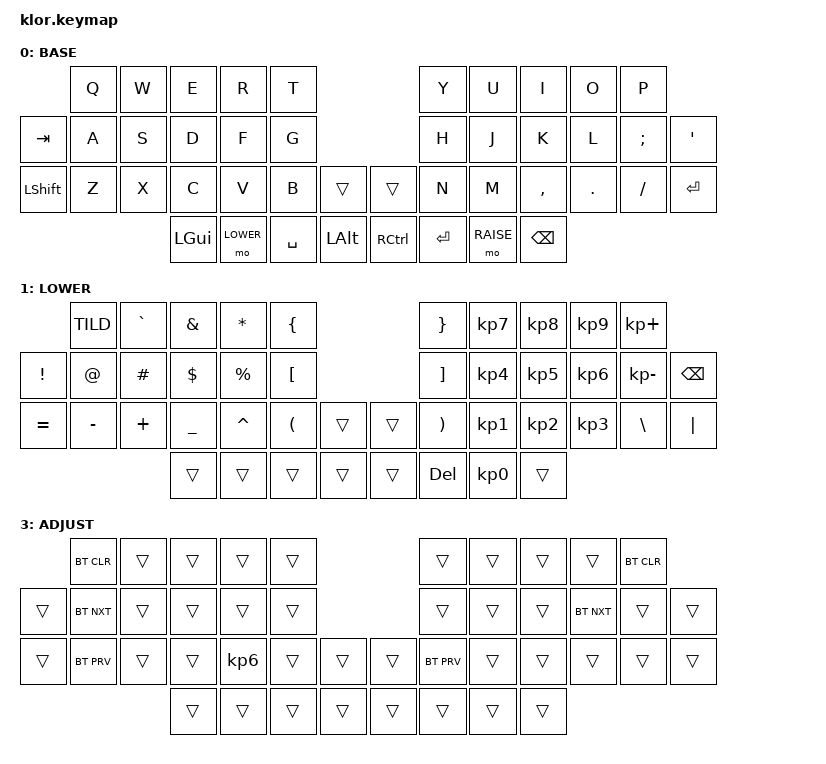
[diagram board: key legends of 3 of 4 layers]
//                               █         █    █            ▄▄▄▀▀▀▀▀▀▄▄▄        █▀▀▀▀▀▀▀▀▀▀█
//                               █        █     █          ▄▀            ▀▄      █          █
//                               █       █      █        ▄▀                ▀▄    █          █
//                               █      █       █        █                  █    █          █
//                               █     █        █       █                    █   █          █
//                               █    █         █       █                    █   █▄▄▄▄▄▄▄▄▄▄█
//                               █   █ █        █       █                    █   █      █
//                               █  █   █       █        █                  █    █       █
//                               █ █     █      █        ▀▄                ▄▀    █        █
//                               ██       █     █          ▀▄            ▄▀      █         █
//                               █         █    █▄▄▄▄▄▄▄▄    ▀▀▀▄▄▄▄▄▄▀▀▀        █          █
//
// ▄▄▄▄▄▄▄▄▄▄▄▄▄▄▄▄▄▄▄▄▄▄▄▄▄▄▄▄▄▄▄▄▄▄▄▄▄▄▄▄▄▄▄▄▄▄▄▄▄▄▄▄▄▄▄▄▄▄▄▄▄▄▄▄▄▄▄▄▄▄▄▄▄▄▄▄▄▄▄▄▄▄▄▄▄▄▄▄▄▄▄▄▄▄▄▄▄▄▄▄▄▄▄▄▄▄▄▄▄▄▄▄▄▄▄▄▄▄▄▄▄▄▄▄▄

#include <behaviors.dtsi>
#include <dt-bindings/zmk/keys.h>
#include <dt-bindings/zmk/bt.h>
#include <dt-bindings/zmk/outputs.h>
#include <dt-bindings/zmk/ext_power.h>
#include <dt-bindings/zmk/rgb.h>

#define BASE   0
#define LOWER  1
#define RAISE  2
#define ADJUST 3

/ {
    behaviors {
        hm: homerow_mods {
            compatible = "zmk,behavior-hold-tap";
            label = "HOMEROW_MODS";
            #binding-cells = <2>;
            tapping-term-ms = <150>;
            quick_tap_ms = <0>;
            flavor = "tap-preferred";
            bindings = <&kp>, <&kp>;
        };

    };

     combos {
            compatible = "zmk,combos";
            combo_esc {
                timeout-ms = <50>;
                key-positions = <0 1>;
                bindings = <&kp ESC>;
            };
    };


        keymap {
                compatible = "zmk,keymap";
// ▄▄▄▄▄▄▄▄▄▄▄▄▄▄▄▄▄▄▄▄▄▄▄▄▄▄▄▄▄▄▄▄▄▄▄▄▄▄▄▄▄▄▄▄▄▄▄▄▄▄▄▄▄▄▄▄▄▄▄▄▄▄▄▄▄▄▄▄▄▄▄▄▄▄▄▄▄▄▄▄▄▄▄▄▄▄▄▄▄▄▄▄▄▄▄▄▄▄▄▄▄▄▄▄▄▄▄▄▄▄▄▄▄▄▄▄▄▄▄▄▄▄▄▄▄▄▄▄▄▄▄▄▄▄▄▄▄▄▄▄▄▄


                base_layer {
// ┌───────────────────────────────────────────────────────────┐
label= "BASE"                                                  ;
// └───────────────────────────────────────────────────────────┘
/*           ┌─────────┬─────────┬─────────┬─────────┬─────────┐                    ┌─────────┬─────────┬─────────┬─────────┬─────────┐
             │    Q    │    W    │    E    │    R    │    T    │                    │    Y    │    U    │    I    │    O    │    P    │
   ┌─────────┼─────────┼─────────┼─────────┼─────────┼─────────┤                    ├─────────┼─────────┼─────────┼─────────┼─────────┼─────────┐
   │   TAB   │    A    │    S    │    D    │    F    │    G    │                    │    H    │    J    │    K    │    L    │    ;    │    '    │
   ├─────────┼─────────┼─────────┼─────────┼─────────┼─────────┤╭────────╮╭────────╮├─────────┼─────────┼─────────┼─────────┼─────────┼─────────┤
   │ LSHIFT  │    Z    │    X    │    C    │    V    │    B    ││  MUTE  ││PLY/PSE ││    N    │    M    │    ,    │    .    │    /    │  ENTER  │
   └─────────┴─────────┴─────────┼─────────┼─────────┼─────────┼╰────────╯╰────────╯┼─────────┼─────────┼─────────┼─────────┴─────────┴─────────┘
                                 │ CMD/WIN │  LOWER  │   ALT   │  SPACE  ││   CTRL  │  ENTER  │  RAISE  │  BSPCE  │
                                 └─────────┴─────────┴─────────┴─────────┘└─────────┴─────────┴─────────┴─────────┘ */
 bindings = <
 //╷         ╷         ╷         ╷         ╷         ╷         ╷         ╷╷         ╷         ╷         ╷         ╷         ╷         ╷         ╷
              &kp Q     &kp W     &kp E     &kp R     &kp T                          &kp Y     &kp U     &kp I     &kp O     &kp P
    &kp TAB   &kp A     &kp S     &kp D   &kp F &kp G                          &kp H   &kp J &kp K     &kp L     &kp SEMI  &kp SQT
    &kp LSHIFT   &kp Z     &kp X     &kp C     &kp V     &kp B     &trans     &trans    &kp N     &kp M     &kp COMMA &kp DOT   &kp FSLH  &kp RET
                                  &kp LGUI &mo LOWER &kp SPACE  &kp LALT  &kp RCTRL  &kp RET   &mo RAISE &kp BSPC
                        >;
            sensor-bindings = <&inc_dec_kp C_VOL_UP C_VOL_DN>;
                };

// ▄▄▄▄▄▄▄▄▄▄▄▄▄▄▄▄▄▄▄▄▄▄▄▄▄▄▄▄▄▄▄▄▄▄▄▄▄▄▄▄▄▄▄▄▄▄▄▄▄▄▄▄▄▄▄▄▄▄▄▄▄▄▄▄▄▄▄▄▄▄▄▄▄▄▄▄▄▄▄▄▄▄▄▄▄▄▄▄▄▄▄▄▄▄▄▄▄▄▄▄▄▄▄▄▄▄▄▄▄▄▄▄▄▄▄▄▄▄▄▄▄▄▄▄▄▄▄▄▄▄▄▄▄▄▄▄▄▄▄▄▄▄



                lower_layer {
// ┌───────────────────────────────────────────────────────────┐
label= "LOWER"                                                 ;
// └───────────────────────────────────────────────────────────┘
/*           ┌─────────┬─────────┬─────────┬─────────┬─────────┐                    ┌─────────┬─────────┬─────────┬─────────┬─────────┐
             │     ~   │     `   │     &   │    *    │    {    │                    │    }    │    7    │    8    │    9    │    +    │
   ┌─────────┼─────────┼─────────┼─────────┼─────────┼─────────┤                    ├─────────┼─────────┼─────────┼─────────┼─────────┼─────────┐
   │    !    │    @    │    #    │    $    │    %    │    [    │                    │    ]    │    4    │    5    │    6    │    -    │  BSPCE  │
   ├─────────┼─────────┼─────────┼─────────┼─────────┼─────────┤╭────────╮╭────────╮├─────────┼─────────┼─────────┼─────────┼─────────┼─────────┤
   │    =    │    -    │    +    │   _     │  ^      │    (    ││        ││        ││    )    │    1    │    2    │    3    │    \    │    |    │
   └─────────┴─────────┴─────────┼─────────┼─────────┼─────────┼╰────────╯╰────────╯┼─────────┼─────────┼─────────┼─────────┴─────────┴─────────┘
                                 │         │         │         │         ││         │         │    0    │         │
                                 └─────────┴─────────┴─────────┴─────────┘└─────────┴─────────┴─────────┴─────────┘ */ 
 bindings = <
 //╷         ╷         ╷         ╷         ╷         ╷         ╷         ╷╷         ╷         ╷         ╷         ╷         ╷         ╷         ╷
    &kp TILD   &kp GRAVE    &kp AMPS    &kp ASTRK    &kp LBRC                       &kp RBRC  &kp KP_N7 &kp KP_N8 &kp KP_N9 &kp KP_PLUS
    &kp EXCL  &kp AT    &kp HASH  &kp DLLR  &kp PERCENT &kp LBKT                       &kp RBKT  &kp KP_N4 &kp KP_N5 &kp KP_N6 &kp KP_MINUS &kp BSPC
    &kp EQUAL &kp MINUS   &kp PLUS &kp UNDER  &kp CARET &kp LPAR  &trans     &trans    &kp RPAR  &kp KP_N1 &kp KP_N2 &kp KP_N3 &kp BSLH &kp PIPE
                                  &trans    &trans    &trans    &trans     &trans    &kp DELETE &kp KP_N0 &trans
                        >;
            sensor-bindings = <&inc_dec_kp C_VOL_UP C_VOL_DN>;
                };

// ▄▄▄▄▄▄▄▄▄▄▄▄▄▄▄▄▄▄▄▄▄▄▄▄▄▄▄▄▄▄▄▄▄▄▄▄▄▄▄▄▄▄▄▄▄▄▄▄▄▄▄▄▄▄▄▄▄▄▄▄▄▄▄▄▄▄▄▄▄▄▄▄▄▄▄▄▄▄▄▄▄▄▄▄▄▄▄▄▄▄▄▄▄▄▄▄▄▄▄▄▄▄▄▄▄▄▄▄▄▄▄▄▄▄▄▄▄▄▄▄▄▄▄▄▄


                raise_layer {
// ┌───────────────────────────────────────────────────────────┐
label= "RAISE"                                                 ;
// └───────────────────────────────────────────────────────────┘
/*           ┌─────────┬─────────┬─────────┬─────────┬─────────┐                    ┌─────────┬─────────┬─────────┬─────────┬─────────┐
             │         │    F1   │    F2   │    F3   │    F4   │                    │         │         │   UP    │         │         │
   ┌─────────┼─────────┼─────────┼─────────┼─────────┼─────────┤                    ├─────────┼─────────┼─────────┼─────────┼─────────┼─────────┐
   │    Ä    │         │    F5   │    F6   │    F7   │    F8   │                    │         │   LEFT  │  DOWN   │  RIGHT  │    Ö    │         │
   ├─────────┼─────────┼─────────┼─────────┼─────────┼─────────┤╭────────╮╭────────╮├─────────┼─────────┼─────────┼─────────┼─────────┼─────────┤
   │         │         │    F9   │   F10   │   F11   │   F12   ││        ││        ││         │   P UP  │         │ P DOWN  │         │         │
   └─────────┴─────────┴─────────┼─────────┼─────────┼─────────┼╰────────╯╰────────╯┼─────────┼─────────┼─────────┼─────────┴─────────┴─────────┘
                                 │ ADJUST  │         │         │         ││  C LOCK │         │         │         │
                                 └─────────┴─────────┴─────────┴─────────┘└─────────┴─────────┴─────────┴─────────┘ */
 bindings = <
 //╷         ╷         ╷         ╷         ╷         ╷         ╷         ╷╷         ╷         ╷         ╷         ╷         ╷         ╷         ╷
              &trans    &trans    &trans    &trans    &trans                         &trans    &trans    &kp UP &trans    &trans
    &kp RA(A) &trans    &kp RA(S) &trans    &trans    &trans                         &trans    &kp LEFT  &kp DOWN  &kp RIGHT    &kp RA(O) &trans
    &trans    &trans    &trans    &trans    &trans    &trans    &trans     &trans    &trans    &kp PG_UP   &kp &trans   &kp PG_DN    &trans    &trans
                                  &mo ADJUST &trans   &trans    &trans     &kp &trans    &trans    &trans    &trans
                        >;
                sensor-bindings = <&inc_dec_kp C_VOL_UP C_VOL_DN>;
                };

// ▄▄▄▄▄▄▄▄▄▄▄▄▄▄▄▄▄▄▄▄▄▄▄▄▄▄▄▄▄▄▄▄▄▄▄▄▄▄▄▄▄▄▄▄▄▄▄▄▄▄▄▄▄▄▄▄▄▄▄▄▄▄▄▄▄▄▄▄▄▄▄▄▄▄▄▄▄▄▄▄▄▄▄▄▄▄▄▄▄▄▄▄▄▄▄▄▄▄▄▄▄▄▄▄▄▄▄▄▄▄▄▄▄▄▄▄▄▄▄▄▄▄▄▄▄


                adjust_layer {
// ┌───────────────────────────────────────────────────────────┐
label= "ADJUST"                                                ;
// └───────────────────────────────────────────────────────────┘
/*           ┌─────────┬─────────┬─────────┬─────────┬─────────┐                    ┌─────────┬─────────┬─────────┬─────────┬─────────┐
             │         │         │         │         │         │                    │         │         │         │         │         │
   ┌─────────┼─────────┼─────────┼─────────┼─────────┼─────────┤                    ├─────────┼─────────┼─────────┼─────────┼─────────┼─────────┐
   │         │         │         │         │         │         │                    │         │         │         │         │         │         │
   ├─────────┼─────────┼─────────┼─────────┼─────────┼─────────┤╭────────╮╭────────╮├─────────┼─────────┼─────────┼─────────┼─────────┼─────────┤
   │         │         │         │         │         │         ││        ││        ││         │         │         │         │         │         │
   └─────────┴─────────┴─────────┼─────────┼─────────┼─────────┼╰────────╯╰────────╯┼─────────┼─────────┼─────────┼─────────┴─────────┴─────────┘
                                 │         │         │         │         ││         │         │         │         │
                                 └─────────┴─────────┴─────────┴─────────┘└─────────┴─────────┴─────────┴─────────┘ */
 bindings = <
 //╷         ╷         ╷         ╷         ╷         ╷         ╷         ╷╷         ╷         ╷         ╷         ╷         ╷         ╷         ╷
             &bt BT_CLR &trans    &trans    &trans    &trans                         &trans    &trans    &trans    &trans    &bt BT_CLR
    &trans   &bt BT_NXT &trans    &trans    &trans    &trans                         &trans    &trans    &trans    &bt BT_NXT &trans   &trans
    &trans   &bt BT_PRV &trans    &trans    &kp KP_N6 &trans    &trans     &trans    &bt BT_PRV &trans   &trans    &trans    &trans    &trans
                                  &trans    &trans    &trans    &trans     &trans    &trans    &trans    &trans
                        >;
            sensor-bindings = <&inc_dec_kp C_VOL_UP C_VOL_DN>;
                };
        };
};
